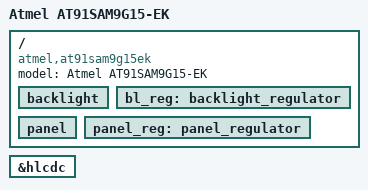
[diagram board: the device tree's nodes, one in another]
/dts-v1/;
#include "at91sam9g15.dtsi"
#include "at91sam9x5dm.dtsi"
#include "at91sam9x5ek.dtsi"
/ {
	model = "Atmel AT91SAM9G15-EK";
	compatible = "atmel,at91sam9g15ek", "atmel,at91sam9x5ek", "atmel,at91sam9x5", "atmel,at91sam9";
	backlight: backlight {
		status = "okay";
	};
	bl_reg: backlight_regulator {
		status = "okay";
	};
	panel: panel {
		status = "okay";
	};
	panel_reg: panel_regulator {
		status = "okay";
	};
};
&hlcdc {
	status = "okay";
};
